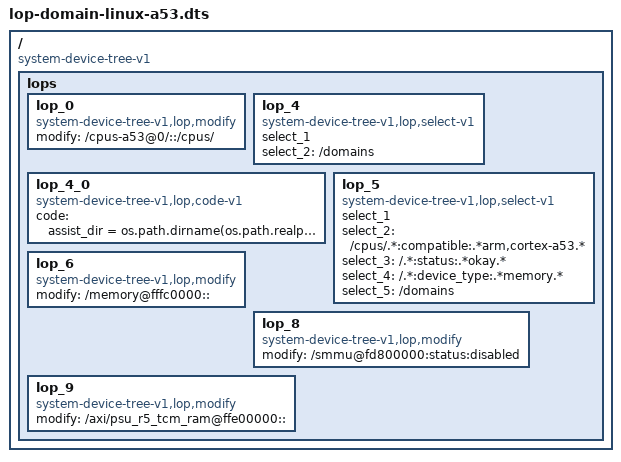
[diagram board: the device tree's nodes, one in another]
/*
 * Copyright (c) 2020 Xilinx Inc. All rights reserved.
 *
 * Author:
 *       Appana Durga Kedareswara Rao <appanad.durga.rao@xilinx.com>
 *
 * SPDX-License-Identifier: BSD-3-Clause
 */

/dts-v1/;

/ {
        compatible = "system-device-tree-v1";
        lops {
                lop_0 {
                        // node name modify
                        compatible = "system-device-tree-v1,lop,modify";
                        modify = "/cpus-a53@0/::/cpus/";
                };

                lop_4 {
                      compatible = "system-device-tree-v1,lop,select-v1";
                      // clear any old selections
                      select_1;
                      select_2 = "/domains";
                };
                lop_4_0 {
                      compatible = "system-device-tree-v1,lop,code-v1";
                      code = "
                          assist_dir = os.path.dirname(os.path.realpath(__file__)) + '/assists/'
                          sys.path.append(assist_dir)
                          from domain_access import update_mem_node
                          from baremetalconfig_xlnx import scan_reg_size
                          # Domain memory handling
                          shared_mem = []
                          memnode_list = tree.nodes('/memory@.*')
                          for n in node.subnodes():
                              if n.propval('memory') != [''] and n.propval('os,type') == ['']:
                                  shared_mem.append(n)
                          for n in node.subnodes():
                              if n.propval('memory') != [''] and  n.propval('os,type') != ['']:
                                  if re.search('linux', n.propval('os,type', list)[0]):
                                      start_addr = n.propval('memory')[0]
                                      linux_shared_mem = []
                                      # Check for resource group
                                      if n.propval('include'):
                                          # Get shared memory nodes for Linux domain
                                          linux_shared_mem = [mem_node for mem_node in shared_mem if mem_node.phandle in n.propval('include')]

                                      for node1 in memnode_list:
                                          reg, size = scan_reg_size(node1, node1['reg'].value, 0)
                                          if start_addr in range(reg, reg+size) and linux_shared_mem:
                                              shared_mem_node = n.propval('memory')
                                              for mem_node in linux_shared_mem:
                                                  shared_mem_node.extend(linux_shared_mem[0].propval('memory'))
                                              modify_val = update_mem_node(node1, shared_mem_node)
                                              node1['reg'].value = modify_val
                                          elif start_addr in range(reg, reg+size):
                                              modify_val = update_mem_node(node1, n.propval('memory'))
                                              node1['reg'].value = modify_val
                      ";
                };
                lop_5 {
                      compatible = "system-device-tree-v1,lop,select-v1";
                      // clear any old selections
                      select_1;
                      select_2 = "/cpus/.*:compatible:.*arm,cortex-a53.*";
                      select_3 = "/.*:status:.*okay.*";
                      select_4 = "/.*:device_type:.*memory.*";
                      select_5 = "/domains";
                };
                lop_6 {
                        // modify to "nothing", is a remove operation
                        compatible = "system-device-tree-v1,lop,modify";
                        modify = "/memory@fffc0000::";
                };

                lop_8 {
                        compatible = "system-device-tree-v1,lop,modify";
                        // Disable SMMU Node
                        modify = "/smmu@fd800000:status:disabled";
                };

                lop_9 {
                        // Delete the duplicate tcm_ram node
                        compatible = "system-device-tree-v1,lop,modify";
                        modify = "/axi/psu_r5_tcm_ram@ffe00000::";
                };
        };
};
